# PIC16F1789 register map
Vendor: Microchip
Registers are 8-bit, read-write, reset 0x0 unless marked. A register's access mark holds for its fields unless they carry their own. Addresses are absolute, and some are shared; only a register's first bit layout is shown; [hi:lo] are bit positions; {n}, {i} and the like mark numbered series.

## CONFIG — Configuration words, addresses in ProgramSpace
0x8007 CONFIG1 14-bit reset 0x3FFF
  [13] FCMEN — Fail-Safe Clock Monitor Enable
    1=ON (Fail-Safe Clock Monitor is enabled); 0=OFF (Fail-Safe Clock Monitor is disabled)
  [12] IESO — Internal/External Switchover
    1=ON (Internal/External Switchover mode is enabled); 0=OFF (Internal/External Switchover mode is disabled)
  [11] CLKOUTEN — Clock Out Enable
    1=OFF (CLKOUT function is disabled. I/O or oscillator function on the CLKOUT pin); 0=ON (CLKOUT function is enabled on the CLKOUT pin)
  [10:9] BOREN — Brown-out Reset Enable
    3=ON (Brown-out Reset enabled); 2=NSLEEP (Brown-out Reset enabled while running and disabled in Sleep); 1=SBODEN (Brown-out Reset controlled by the SBOREN bit in the BORCON register); 0=OFF (Brown-out Reset disabled)
  [8] CPD — Data Memory Code Protection
    1=OFF (Data memory code protection is disabled); 0=ON (Data memory code protection is enabled)
  [7] CP — Flash Program Memory Code Protection
    1=OFF (Program memory code protection is disabled); 0=ON (Program memory code protection is enabled)
  [6] MCLRE — MCLR Pin Function Select
    1=ON (MCLR/VPP pin function is MCLR); 0=OFF (MCLR/VPP pin function is digital input)
  [5] PWRTE — Power-up Timer Enable
    1=OFF (PWRT disabled); 0=ON (PWRT enabled)
  [4:3] WDTE — Watchdog Timer Enable
    3=ON (WDT enabled); 2=NSLEEP (WDT enabled while running and disabled in Sleep); 1=SWDTEN (WDT controlled by the SWDTEN bit in the WDTCON register); 0=OFF (WDT disabled)
  [2:0] FOSC — Oscillator Selection
    7=ECH (ECH, External Clock, High Power Mode (4-32 MHz): device clock supplied to CLKIN pin); 6=ECM (ECM, External Clock, Medium Power Mode (0.5-4 MHz): device clock supplied to CLKIN pin); 5=ECL (ECL, External Clock, Low Power Mode (0-0.5 MHz): device clock supplied to CLKIN pin); 4=INTOSC (INTOSC oscillator: I/O function on CLKIN pin); 3=EXTRC (EXTRC oscillator: External RC circuit connected to CLKIN pin); 2=HS (HS Oscillator, High-speed crystal/resonator connected between OSC1 and OSC2 pins); 1=XT (XT Oscillator, Crystal/resonator connected between OSC1 and OSC2 pins); 0=LP (LP Oscillator, Low-power crystal connected between OSC1 and OSC2 pins)
0x8008 CONFIG2 14-bit reset 0x3FFF
  [13] LVP — Low-Voltage Programming Enable
    1=ON (Low-voltage programming enabled); 0=OFF (High-voltage on MCLR/VPP must be used for programming)
  [12] DEBUG — In-Circuit Debugger Mode
    1=OFF (In-Circuit Debugger disabled, ICSPCLK and ICSPDAT are general purpose I/O pins); 0=ON (In-Circuit Debugger enabled, ICSPCLK and ICSPDAT are dedicated to the debugger)
  [11] LPBOR — Low Power Brown-Out Reset Enable Bit
    1=OFF (Low power brown-out is disabled); 0=ON (Low power brown-out is enabled)
  [10] BORV — Brown-out Reset Voltage Selection
    1=LO (Brown-out Reset Voltage (Vbor), low trip point selected.); 0=HI (Brown-out Reset Voltage (Vbor), high trip point selected.)
  [9] STVREN — Stack Overflow/Underflow Reset Enable
    1=ON (Stack Overflow or Underflow will cause a Reset); 0=OFF (Stack Overflow or Underflow will not cause a Reset)
  [8] PLLEN — PLL Enable
    1=ON (4x PLL enabled); 0=OFF (4x PLL disabled)
  [5] VCAPEN — Voltage Regulator Capacitor Enable bit
    1=OFF (Vcap functionality is disabled on RA6.); 0=ON (Vcap functionality is enabled on RA6 (Vddcore is connected to the pad))
  [1:0] WRT — Flash Memory Self-Write Protection
    3=OFF (Write protection off); 2=BOOT (000h to 1FFh write protected, 200h to 1FFFh may be modified by EECON control); 1=HALF (000h to FFFh write protected, 1000h to 1FFFh may be modified by EECON control); 0=ALL (000h to 7FFh write protected, no addresses may be modified by EECON control)

## DOS_OPAMP_amp_opamp_hvpump
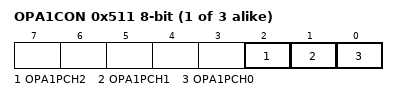
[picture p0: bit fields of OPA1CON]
{0x50F+2i} OPA{i}CON (i=1..3)
  [2] OPA{i}PCH2, [1] OPA{i}PCH1, [0] OPA{i}PCH0

## 5bit_DAC
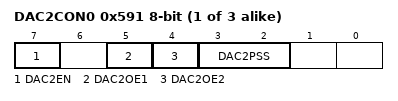
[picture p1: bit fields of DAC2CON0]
{0x58D+2i} DAC{i}CON0 (i=2..4)
  [7] DAC{i}EN, [5] DAC{i}OE1, [4] DAC{i}OE2, [3:2] DAC{i}PSS
{0x58E+2i} DAC{i}REF (i=2..4)
  [4:0] DAC{i}R
